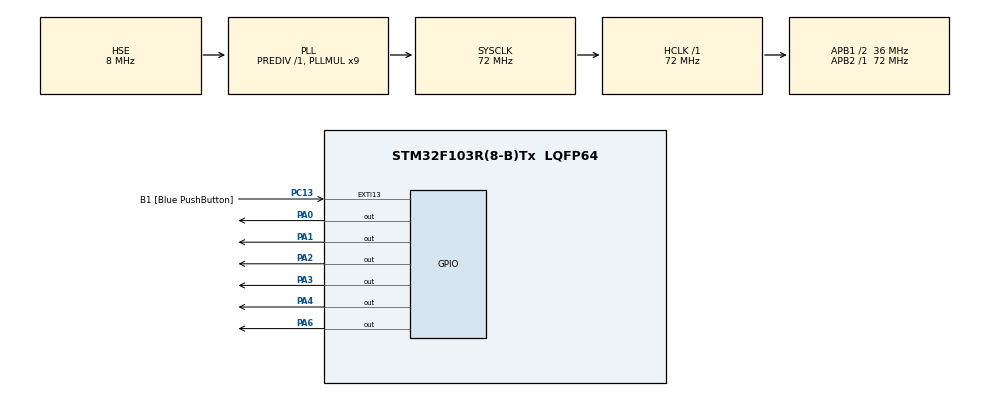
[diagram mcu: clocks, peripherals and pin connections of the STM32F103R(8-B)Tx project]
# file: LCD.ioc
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Mcu.Family=STM32F1
Mcu.Name=STM32F103R(8-B)Tx
Mcu.Package=LQFP64
NVIC.EXTI15_10_IRQn=true\:0\:0\:false\:false\:true\:true\:true\:true
NVIC.PriorityGroup=NVIC_PRIORITYGROUP_4
PA0-WKUP.Signal=GPIO_Output
PA1.Signal=GPIO_Output
PA13.GPIO_Label=TMS
PA13.Mode=Serial_Wire
PA13.Signal=SYS_JTMS-SWDIO
PA14.GPIO_Label=TCK
PA14.Mode=Serial_Wire
PA14.Signal=SYS_JTCK-SWCLK
PA2.Signal=GPIO_Output
PA3.Signal=GPIO_Output
PA4.Signal=GPIO_Output
PA6.Signal=GPIO_Output
PB3.GPIO_Label=SWO
PB3.Signal=SYS_JTDO-TRACESWO
PC13-TAMPER-RTC.GPIO_Label=B1 [Blue PushButton]
PC13-TAMPER-RTC.GPIO_ModeDefaultEXTI=GPIO_MODE_IT_FALLING
PC13-TAMPER-RTC.GPIO_PuPd=GPIO_NOPULL
PC13-TAMPER-RTC.Signal=GPXTI13
PC14-OSC32_IN.Signal=RCC_OSC32_IN
PC15-OSC32_OUT.Signal=RCC_OSC32_OUT
PD0-OSC_IN.Mode=HSE-External-Oscillator
PD0-OSC_IN.Signal=RCC_OSC_IN
PD1-OSC_OUT.Mode=HSE-External-Oscillator
PD1-OSC_OUT.Signal=RCC_OSC_OUT
ProjectManager.HeapSize=0x200
ProjectManager.StackSize=0x400
ProjectManager.TargetToolchain=STM32CubeIDE
RCC.AHBFreq_Value=72000000
RCC.APB1CLKDivider=RCC_HCLK_DIV2
RCC.APB1Freq_Value=36000000
RCC.APB1TimFreq_Value=72000000
RCC.APB2Freq_Value=72000000
RCC.APB2TimFreq_Value=72000000
RCC.HCLKFreq_Value=72000000
RCC.PLLMUL=RCC_PLL_MUL9
RCC.PLLSourceVirtual=RCC_PLLSOURCE_HSE
RCC.SYSCLKFreq_VALUE=72000000
RCC.SYSCLKSource=RCC_SYSCLKSOURCE_PLLCLK
RCC.USBFreq_Value=72000000
TIM1.Period=0xffff-1
TIM1.Prescaler=72-1
VP_TIM1_VS_ClockSourceINT.Mode=Internal
board=NUCLEO-F103RB

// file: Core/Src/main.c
/* USER CODE BEGIN Header */
/**
  ******************************************************************************
  * @file           : main.c
  * @brief          : Main program body
  ******************************************************************************
  * @attention
  *
  * Copyright (c) 2023 STMicroelectronics.
  * All rights reserved.
  *
  * This software is licensed under terms that can be found in the LICENSE file
  * in the root directory of this software component.
  * If no LICENSE file comes with this software, it is provided AS-IS.
  *
  ******************************************************************************
  */
/* USER CODE END Header */
#include "main.h"

/* USER CODE BEGIN Includes */
#include "lcd.h"
/* USER CODE END Includes */

TIM_HandleTypeDef htim1;

void SystemClock_Config(void);
static void MX_GPIO_Init(void);
static void MX_TIM1_Init(void);

int main(void)
{

  /* MCU Configuration--------------------------------------------------------*/

  /* Reset of all peripherals, Initializes the Flash interface and the Systick. */
  HAL_Init();

  /* Configure the system clock */
  SystemClock_Config();

  /* Initialize all configured peripherals */
  MX_GPIO_Init();
  MX_TIM1_Init();
  /* USER CODE BEGIN 2 */
// Lcd_PortType ports[] = { D4_GPIO_Port, D5_GPIO_Port, D6_GPIO_Port, D7_GPIO_Port };
  Lcd_PortType ports[] = { GPIOA, GPIOA, GPIOA, GPIOA };
  // Lcd_PinType pins[] = {D4_Pin, D5_Pin, D6_Pin, D7_Pin};
  Lcd_PinType pins[] = {GPIO_PIN_2, GPIO_PIN_3, GPIO_PIN_4, GPIO_PIN_6};
  Lcd_HandleTypeDef lcd;
  // Lcd_create(ports, pins, RS_GPIO_Port, RS_Pin, EN_GPIO_Port, EN_Pin, LCD_4_BIT_MODE);
  lcd = Lcd_create(ports, pins, GPIOA, GPIO_PIN_0, GPIOA, GPIO_PIN_1, LCD_4_BIT_MODE);
  Lcd_cursor(&lcd, 0,1);
  Lcd_string(&lcd, "Hassane Lahrar");
    for ( int x = 1; x <= 200 ; x++ )
    {
      Lcd_cursor(&lcd, 1,7);
      Lcd_int(&lcd, x);
      HAL_Delay (1000);
    }

  /* USER CODE END 2 */

  /* Infinite loop */
  while (1)
  {

  }
}

void SystemClock_Config(void)
{
  RCC_OscInitTypeDef RCC_OscInitStruct = {0};
  RCC_ClkInitTypeDef RCC_ClkInitStruct = {0};

  /** Initializes the RCC Oscillators according to the specified parameters
  * in the RCC_OscInitTypeDef structure.
  */
  RCC_OscInitStruct.OscillatorType = RCC_OSCILLATORTYPE_HSE;
  RCC_OscInitStruct.HSEState = RCC_HSE_ON;
  RCC_OscInitStruct.HSEPredivValue = RCC_HSE_PREDIV_DIV1;
  RCC_OscInitStruct.HSIState = RCC_HSI_ON;
  RCC_OscInitStruct.PLL.PLLState = RCC_PLL_ON;
  RCC_OscInitStruct.PLL.PLLSource = RCC_PLLSOURCE_HSE;
  RCC_OscInitStruct.PLL.PLLMUL = RCC_PLL_MUL9;
  if (HAL_RCC_OscConfig(&RCC_OscInitStruct) != HAL_OK)
  {
    Error_Handler();
  }

  /** Initializes the CPU, AHB and APB buses clocks
  */
  RCC_ClkInitStruct.ClockType = RCC_CLOCKTYPE_HCLK|RCC_CLOCKTYPE_SYSCLK
                              |RCC_CLOCKTYPE_PCLK1|RCC_CLOCKTYPE_PCLK2;
  RCC_ClkInitStruct.SYSCLKSource = RCC_SYSCLKSOURCE_PLLCLK;
  RCC_ClkInitStruct.AHBCLKDivider = RCC_SYSCLK_DIV1;
  RCC_ClkInitStruct.APB1CLKDivider = RCC_HCLK_DIV2;
  RCC_ClkInitStruct.APB2CLKDivider = RCC_HCLK_DIV1;

  if (HAL_RCC_ClockConfig(&RCC_ClkInitStruct, FLASH_LATENCY_2) != HAL_OK)
  {
    Error_Handler();
  }
}

static void MX_TIM1_Init(void)
{

  TIM_ClockConfigTypeDef sClockSourceConfig = {0};
  TIM_MasterConfigTypeDef sMasterConfig = {0};

  htim1.Instance = TIM1;
  htim1.Init.Prescaler = 72-1;
  htim1.Init.CounterMode = TIM_COUNTERMODE_UP;
  htim1.Init.Period = 0xffff-1;
  htim1.Init.ClockDivision = TIM_CLOCKDIVISION_DIV1;
  htim1.Init.RepetitionCounter = 0;
  htim1.Init.AutoReloadPreload = TIM_AUTORELOAD_PRELOAD_DISABLE;
  if (HAL_TIM_Base_Init(&htim1) != HAL_OK)
  {
    Error_Handler();
  }
  sClockSourceConfig.ClockSource = TIM_CLOCKSOURCE_INTERNAL;
  if (HAL_TIM_ConfigClockSource(&htim1, &sClockSourceConfig) != HAL_OK)
  {
    Error_Handler();
  }
  sMasterConfig.MasterOutputTrigger = TIM_TRGO_RESET;
  sMasterConfig.MasterSlaveMode = TIM_MASTERSLAVEMODE_DISABLE;
  if (HAL_TIMEx_MasterConfigSynchronization(&htim1, &sMasterConfig) != HAL_OK)
  {
    Error_Handler();
  }

}

static void MX_GPIO_Init(void)
{
  GPIO_InitTypeDef GPIO_InitStruct = {0};

  /* GPIO Ports Clock Enable */
  __HAL_RCC_GPIOC_CLK_ENABLE();
  __HAL_RCC_GPIOD_CLK_ENABLE();
  __HAL_RCC_GPIOA_CLK_ENABLE();
  __HAL_RCC_GPIOB_CLK_ENABLE();

  /*Configure GPIO pin Output Level */
  HAL_GPIO_WritePin(GPIOA, GPIO_PIN_0|GPIO_PIN_1|GPIO_PIN_2|GPIO_PIN_3
                          |GPIO_PIN_4|GPIO_PIN_6, GPIO_PIN_RESET);

  /*Configure GPIO pin : B1_Pin */
  GPIO_InitStruct.Pin = B1_Pin;
  GPIO_InitStruct.Mode = GPIO_MODE_IT_FALLING;
  GPIO_InitStruct.Pull = GPIO_NOPULL;
  HAL_GPIO_Init(B1_GPIO_Port, &GPIO_InitStruct);

  /*Configure GPIO pins : PA0 PA1 PA2 PA3
                           PA4 PA6 */
  GPIO_InitStruct.Pin = GPIO_PIN_0|GPIO_PIN_1|GPIO_PIN_2|GPIO_PIN_3
                          |GPIO_PIN_4|GPIO_PIN_6;
  GPIO_InitStruct.Mode = GPIO_MODE_OUTPUT_PP;
  GPIO_InitStruct.Pull = GPIO_NOPULL;
  GPIO_InitStruct.Speed = GPIO_SPEED_FREQ_LOW;
  HAL_GPIO_Init(GPIOA, &GPIO_InitStruct);

  /* EXTI interrupt init*/
  HAL_NVIC_SetPriority(EXTI15_10_IRQn, 0, 0);
  HAL_NVIC_EnableIRQ(EXTI15_10_IRQn);

}

void Error_Handler(void)
{
  __disable_irq();
  while (1)
  {
  }
}
